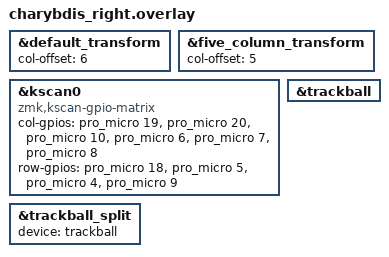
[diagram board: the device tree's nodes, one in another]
#include "charybdis.dtsi"
#include "charybdis_pmw3610.dtsi"
#include "charybdis_pointer.dtsi"

// The matrix transform is 6 columns over because the left half is 6 columns wide.
&default_transform {
	col-offset = <6>;
};

&five_column_transform {
	col-offset = <5>;
};

&kscan0 {
	compatible = "zmk,kscan-gpio-matrix";
	
	col-gpios
		= <&pro_micro 19 (GPIO_ACTIVE_HIGH | GPIO_PULL_DOWN)>
		, <&pro_micro 20 (GPIO_ACTIVE_HIGH | GPIO_PULL_DOWN)>
		, <&pro_micro 10 (GPIO_ACTIVE_HIGH | GPIO_PULL_DOWN)>
		, <&pro_micro 6 (GPIO_ACTIVE_HIGH | GPIO_PULL_DOWN)>
		, <&pro_micro 7 (GPIO_ACTIVE_HIGH | GPIO_PULL_DOWN)>
		, <&pro_micro 8 (GPIO_ACTIVE_HIGH | GPIO_PULL_DOWN)>
		;

	row-gpios
		= <&pro_micro 18 GPIO_ACTIVE_HIGH>
		, <&pro_micro 5 GPIO_ACTIVE_HIGH>
		, <&pro_micro 4 GPIO_ACTIVE_HIGH>
		, <&pro_micro 9 GPIO_ACTIVE_HIGH>
		;
};

&trackball {
  status = "okay";
};

/* Enable the trackball listener on the peripheral with the sensor */
&trackball_split {
  device = <&trackball>;
  status = "okay";
};
